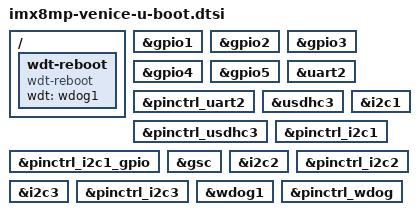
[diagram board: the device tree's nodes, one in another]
// SPDX-License-Identifier: (GPL-2.0+ OR MIT)
/*
 * Copyright 2022 Gateworks Corporation
 */

#include "imx8mp-u-boot.dtsi"

/ {
	wdt-reboot {
		compatible = "wdt-reboot";
		wdt = <&wdog1>;
		bootph-pre-ram;
	};
};

&gpio1 {
	bootph-pre-ram;
};

&gpio2 {
	bootph-pre-ram;
};

&gpio3 {
	bootph-pre-ram;
};

&gpio4 {
	bootph-pre-ram;
};

&gpio5 {
	bootph-pre-ram;
};

&uart2 {
	bootph-pre-ram;
};

&pinctrl_uart2 {
	bootph-pre-ram;
};

&usdhc3 {
	bootph-pre-ram;
};

&pinctrl_usdhc3 {
	bootph-pre-ram;
};

&i2c1 {
	bootph-pre-ram;
};

&pinctrl_i2c1 {
	bootph-pre-ram;
};

&pinctrl_i2c1_gpio {
	bootph-pre-ram;
};

&gsc {
	bootph-pre-ram;
};

&i2c2 {
	bootph-pre-ram;
};

&pinctrl_i2c2 {
	bootph-pre-ram;
};

&i2c3 {
	bootph-pre-ram;
};

&pinctrl_i2c3 {
	bootph-pre-ram;
};

&wdog1 {
	bootph-pre-ram;
};

&pinctrl_wdog {
	bootph-pre-ram;
};
